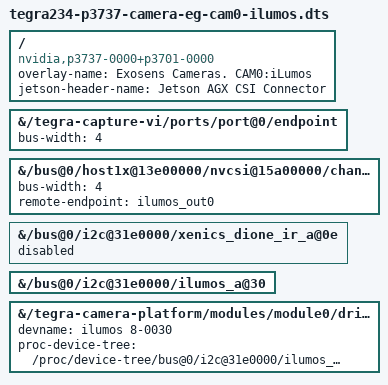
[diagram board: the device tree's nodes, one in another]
// SPDX-License-Identifier: GPL-2.0-only

/dts-v1/;
/plugin/;

/ {
	overlay-name = "Exosens Cameras. CAM0:iLumos";
	jetson-header-name = "Jetson AGX CSI Connector";
	compatible = "nvidia,p3737-0000+p3701-0000", "nvidia,p3737-0000+p3701-0004", "nvidia,p3737-0000+p3701-0005";

	fragment@0 {
		target-path = "/tegra-capture-vi/ports/port@0/endpoint";
		__overlay__ {
			bus-width=<4>;
		};
	};

	fragment@1 {
		target-path = "/bus@0/host1x@13e00000/nvcsi@15a00000/channel@0/ports/port@0/endpoint@0";
		__overlay__ {
			bus-width=<4>;
			remote-endpoint = <&ilumos_out0>;
		};
	};

	// Disable Dione cameras
	fragment@2 {
		target-path = "/bus@0/i2c@31e0000/xenics_dione_ir_a@0e";
		__overlay__ {
			status = "disabled";
		};
	};

	// Enable iLumos
	fragment@3 {
		target-path = "/bus@0/i2c@31e0000/ilumos_a@30";
		__overlay__ {
			status = "okay";
		};
	};

	fragment@4 {
		target-path = "/tegra-camera-platform/modules/module0/drivernode0";
		__overlay__ {
			devname = "ilumos 8-0030";
			proc-device-tree = "/proc/device-tree/bus@0/i2c@31e0000/ilumos_a@30";
		};
	};

};
